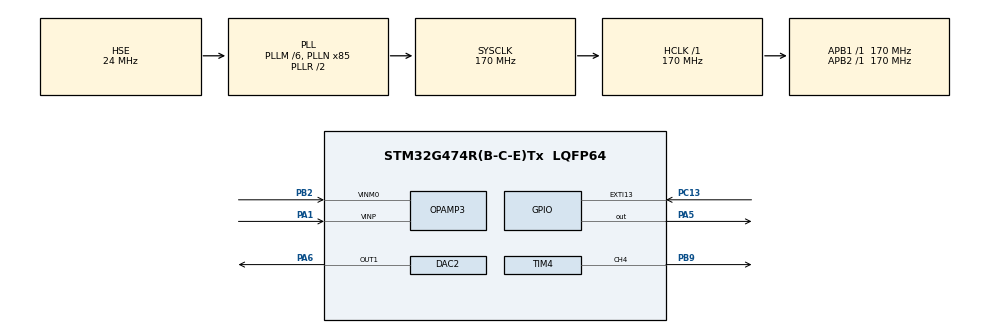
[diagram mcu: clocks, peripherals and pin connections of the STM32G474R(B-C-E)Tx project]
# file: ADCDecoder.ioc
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ADC2.AWD2HighThreshold=0xFD0
ADC2.AWD2LowThreshold=0x20
ADC2.AWDChannel-1\#ChannelRegularConversion=ADC_CHANNEL_VOPAMP3_ADC2
ADC2.Channel-1\#ChannelRegularConversion=ADC_CHANNEL_VOPAMP3_ADC2
ADC2.DMAContinuousRequests=ENABLE
ADC2.EnableAnalogWatchDog2=true
ADC2.EnableAnalogWatchDog3=false
ADC2.ExternalTrigConv=ADC_EXTERNALTRIG_T4_CC4
ADC2.GainCompensation=0
ADC2.MonitoredBy-1\#ChannelRegularConversion=ADC_ANALOGWATCHDOG_2
ADC2.NbrOfConversionFlag=1
ADC2.Offset-1\#ChannelRegularConversion=2048
ADC2.OffsetNumber-1\#ChannelRegularConversion=ADC_OFFSET_NONE
ADC2.Overrun=ADC_OVR_DATA_OVERWRITTEN
ADC2.Rank-1\#ChannelRegularConversion=1
ADC2.RegFilteringConfig-1\#ChannelRegularConversion=ADC_AWD_FILTERING_NONE
ADC2.SamplingTime-1\#ChannelRegularConversion=ADC_SAMPLETIME_2CYCLES_5
ADC2.WDG2ChannelR1=ADC_CHANNEL_VOPAMP3_ADC2
ADC2.WatchdogMode2=ADC_ANALOGWATCHDOG_SINGLE_REGINJEC
DAC2.DAC_DMADoubleDataMode-DAC_OUT1=DISABLE
DAC2.DAC_SignedFormat-DAC_OUT1=DISABLE
Dma.ADC2.1.Direction=DMA_PERIPH_TO_MEMORY
Dma.ADC2.1.EventEnable=DISABLE
Dma.ADC2.1.Instance=DMA1_Channel1
Dma.ADC2.1.MemDataAlignment=DMA_MDATAALIGN_WORD
Dma.ADC2.1.MemInc=DMA_MINC_DISABLE
Dma.ADC2.1.Mode=DMA_CIRCULAR
Dma.ADC2.1.PeriphDataAlignment=DMA_PDATAALIGN_HALFWORD
Dma.ADC2.1.PeriphInc=DMA_PINC_DISABLE
Dma.ADC2.1.Polarity=HAL_DMAMUX_REQ_GEN_RISING
Dma.ADC2.1.Priority=DMA_PRIORITY_LOW
Dma.ADC2.1.RequestNumber=1
Dma.ADC2.1.SignalID=NONE
Dma.ADC2.1.SyncEnable=DISABLE
Dma.ADC2.1.SyncPolarity=HAL_DMAMUX_SYNC_NO_EVENT
Dma.ADC2.1.SyncRequestNumber=1
Dma.ADC2.1.SyncSignalID=NONE
Dma.FMAC_READ.0.Direction=DMA_PERIPH_TO_MEMORY
Dma.FMAC_READ.0.EventEnable=DISABLE
Dma.FMAC_READ.0.Instance=DMA1_Channel3
Dma.FMAC_READ.0.MemDataAlignment=DMA_MDATAALIGN_WORD
Dma.FMAC_READ.0.MemInc=DMA_MINC_DISABLE
Dma.FMAC_READ.0.Mode=DMA_CIRCULAR
Dma.FMAC_READ.0.PeriphDataAlignment=DMA_PDATAALIGN_WORD
Dma.FMAC_READ.0.PeriphInc=DMA_PINC_DISABLE
Dma.FMAC_READ.0.Polarity=HAL_DMAMUX_REQ_GEN_RISING
Dma.FMAC_READ.0.Priority=DMA_PRIORITY_LOW
Dma.FMAC_READ.0.RequestNumber=1
Dma.FMAC_READ.0.SignalID=NONE
Dma.FMAC_READ.0.SyncEnable=DISABLE
Dma.FMAC_READ.0.SyncPolarity=HAL_DMAMUX_SYNC_NO_EVENT
Dma.FMAC_READ.0.SyncRequestNumber=1
Dma.FMAC_READ.0.SyncSignalID=NONE
Dma.MEMTOMEM.2.Direction=DMA_MEMORY_TO_MEMORY
Dma.MEMTOMEM.2.EventEnable=DISABLE
Dma.MEMTOMEM.2.Instance=DMA2_Channel2
Dma.MEMTOMEM.2.MemDataAlignment=DMA_MDATAALIGN_WORD
Dma.MEMTOMEM.2.MemInc=DMA_MINC_ENABLE
Dma.MEMTOMEM.2.Mode=DMA_NORMAL
Dma.MEMTOMEM.2.PeriphDataAlignment=DMA_PDATAALIGN_WORD
Dma.MEMTOMEM.2.PeriphInc=DMA_PINC_ENABLE
Dma.MEMTOMEM.2.Polarity=HAL_DMAMUX_REQ_GEN_RISING
Dma.MEMTOMEM.2.Priority=DMA_PRIORITY_LOW
Dma.MEMTOMEM.2.RequestNumber=1
Dma.MEMTOMEM.2.SignalID=NONE
Dma.MEMTOMEM.2.SyncEnable=DISABLE
Dma.MEMTOMEM.2.SyncPolarity=HAL_DMAMUX_SYNC_NO_EVENT
Dma.MEMTOMEM.2.SyncRequestNumber=1
Dma.MEMTOMEM.2.SyncSignalID=NONE
Dma.MEMTOMEM.3.Direction=DMA_MEMORY_TO_MEMORY
Dma.MEMTOMEM.3.EventEnable=DISABLE
Dma.MEMTOMEM.3.Instance=DMA1_Channel2
Dma.MEMTOMEM.3.MemDataAlignment=DMA_MDATAALIGN_WORD
Dma.MEMTOMEM.3.MemInc=DMA_MINC_ENABLE
Dma.MEMTOMEM.3.Mode=DMA_NORMAL
Dma.MEMTOMEM.3.PeriphDataAlignment=DMA_PDATAALIGN_WORD
Dma.MEMTOMEM.3.PeriphInc=DMA_PINC_ENABLE
Dma.MEMTOMEM.3.Polarity=HAL_DMAMUX_REQ_GEN_RISING
Dma.MEMTOMEM.3.Priority=DMA_PRIORITY_LOW
Dma.MEMTOMEM.3.RequestNumber=1
Dma.MEMTOMEM.3.SignalID=NONE
Dma.MEMTOMEM.3.SyncEnable=DISABLE
Dma.MEMTOMEM.3.SyncPolarity=HAL_DMAMUX_SYNC_NO_EVENT
Dma.MEMTOMEM.3.SyncRequestNumber=1
Dma.MEMTOMEM.3.SyncSignalID=NONE
Dma.Request0=FMAC_READ
Dma.Request1=ADC2
Dma.Request2=MEMTOMEM
Dma.Request3=MEMTOMEM
Mcu.Family=STM32G4
Mcu.Name=STM32G474R(B-C-E)Tx
Mcu.Package=LQFP64
NUCLEO-G474RE.BUTTON=1
NUCLEO-G474RE.Bsp_Common_DEMO=true
NUCLEO-G474RE.LD2=true
NUCLEO-G474RE.VCP=true
NVIC.DMA1_Channel1_IRQn=true\:0\:0\:false\:false\:true\:false\:true\:true
NVIC.DMA1_Channel2_IRQn=true\:0\:0\:false\:false\:true\:true\:true\:true
NVIC.DMA1_Channel3_IRQn=true\:0\:0\:false\:false\:true\:false\:true\:true
NVIC.DMA2_Channel2_IRQn=true\:0\:0\:false\:false\:true\:true\:true\:true
NVIC.EXTI15_10_IRQn=true\:0\:0\:false\:false\:true\:true\:true\:true
NVIC.PriorityGroup=NVIC_PRIORITYGROUP_4
NVIC.TIM1_UP_TIM16_IRQn=true\:0\:0\:false\:false\:true\:true\:true\:true
NVIC.TIM3_IRQn=true\:0\:0\:false\:false\:true\:true\:true\:true
NVIC.TIM5_IRQn=true\:0\:0\:false\:false\:true\:true\:true\:true
OPAMP3.PgaGain=OPAMP_PGA_GAIN_2_OR_MINUS_1
OPAMP3.PowerMode=OPAMP_POWERMODE_HIGHSPEED
OPAMP3.SelfCalibration=Enable
OPAMP3.UserTrimming=OPAMP_TRIMMING_USER
PA1.Mode=PGA Internally connected_IO0_IO1_BIAS
PA1.Signal=OPAMP3_VINP
PA13.GPIO_Label=T_SWDIO
PA13.Signal=SYS_JTMS-SWDIO
PA14.GPIO_Label=T_SWCLK
PA14.Signal=SYS_JTCK-SWCLK
PA2.Signal=LPUART1_TX
PA3.Signal=LPUART1_RX
PA5.Signal=GPIO_Output
PA6.Signal=COMP_DAC21_group
PB2.Mode=PGA Internally connected_IO0_IO1_BIAS
PB2.Signal=OPAMP3_VINM0
PB3.GPIO_Label=T_SWO
PB3.Signal=SYS_JTDO-SWO
PB9.Signal=S_TIM4_CH4
PC13.Signal=GPXTI13
PC14-OSC32_IN.GPIO_Label=RCC_OSC32_IN
PC14-OSC32_IN.Signal=RCC_OSC32_IN
PC15-OSC32_OUT.GPIO_Label=RCC_OSC32_OUT
PC15-OSC32_OUT.Signal=RCC_OSC32_OUT
PF0-OSC_IN.GPIO_Label=RCC_OSC_IN
PF0-OSC_IN.Mode=HSE-External-Oscillator
PF0-OSC_IN.Signal=RCC_OSC_IN
PF1-OSC_OUT.GPIO_Label=RCC_OSC_OUT
PF1-OSC_OUT.Mode=HSE-External-Oscillator
PF1-OSC_OUT.Signal=RCC_OSC_OUT
ProjectManager.HeapSize=0x200
ProjectManager.StackSize=0x400
ProjectManager.TargetToolchain=STM32CubeIDE
RCC.ADC12Freq_Value=170000000
RCC.ADC345Freq_Value=170000000
RCC.AHBFreq_Value=170000000
RCC.APB1Freq_Value=170000000
RCC.APB1TimFreq_Value=170000000
RCC.APB2Freq_Value=170000000
RCC.APB2TimFreq_Value=170000000
RCC.CK48CLockSelection=RCC_USBCLKSOURCE_HSI48
RCC.CortexFreq_Value=170000000
RCC.EXTERNAL_CLOCK_VALUE=12288000
RCC.HCLKFreq_Value=170000000
RCC.HSE_VALUE=24000000
RCC.HSI48_VALUE=48000000
RCC.HSI_VALUE=16000000
RCC.LSE_VALUE=32768
RCC.PLLM=RCC_PLLM_DIV6
RCC.PLLN=85
RCC.PLLSourceVirtual=RCC_PLLSOURCE_HSE
RCC.RTCClockSelection=RCC_RTCCLKSOURCE_LSE
RCC.SYSCLKFreq_VALUE=170000000
RCC.SYSCLKSource=RCC_SYSCLKSOURCE_PLLCLK
RCC.USBFreq_Value=48000000
RCC.VCOOutputFreq_Value=340000000
RNG.ClockErrorDetection=RNG_CED_DISABLE
SH.COMP_DAC21_group.0=DAC2_OUT1,DAC_OUT1
SH.S_TIM4_CH4.0=TIM4_CH4,PWM Generation4 CH4
TIM1.PeriodNoDither=49
TIM1.Prescaler=16
TIM2.Prescaler=16
TIM3.TIM3_ETR_REMAP-ClockSourceETR_Mode2_Remap_TIM3=TIM_TIM3_ETR_ADC2_AWD2
TIM3.TIM_MasterOutputTrigger=TIM_TRGO_RESET
TIM4.Channel-PWM\ Generation4\ CH4=TIM_CHANNEL_4
TIM4.PeriodNoDither=424
TIM4.Prescaler=0
TIM4.PulseNoDither_4=212
TIM5.AutoReloadPreload=TIM_AUTORELOAD_PRELOAD_DISABLE
TIM5.PeriodNoDither=999999
TIM5.Prescaler=169
VP_ADC2_OPAMP_INTERNAL3.Mode=IN-OPAMP3
VP_FMAC_VS_FMAC.Mode=FMAC_Activate
VP_NUCLEO-G474RE_VS_BSP_COMMON.Mode=COMMON
VP_RNG_VS_RNG.Mode=RNG_Activate
VP_SYS_VS_DBSignals.Mode=DisableDeadBatterySignals
VP_TIM1_VS_ClockSourceINT.Mode=Internal
VP_TIM2_VS_ClockSourceINT.Mode=Internal
VP_TIM3_VS_NoETR.Mode=ClockSourceETR_Mode2_Remap_TIM3
VP_TIM4_VS_ClockSourceINT.Mode=Internal
VP_TIM5_VS_ClockSourceINT.Mode=Internal
board=NUCLEO-G474RE

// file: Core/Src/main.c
/* USER CODE BEGIN Header */
/**
  ******************************************************************************
  * @file           : main.c
  * @brief          : Main program body
  ******************************************************************************
  * @attention
  *
  * Copyright (c) 2024 STMicroelectronics.
  * All rights reserved.
  *
  * This software is licensed under terms that can be found in the LICENSE file
  * in the root directory of this software component.
  * If no LICENSE file comes with this software, it is provided AS-IS.
  *
  ******************************************************************************
  */
/* USER CODE END Header */
#include "main.h"
#include "adc.h"
#include "dac.h"
#include "dma.h"
#include "fmac.h"
#include "opamp.h"
#include "rng.h"
#include "tim.h"
#include "gpio.h"

COM_InitTypeDef BspCOMInit;
__IO uint32_t BspButtonState = BUTTON_RELEASED;

void SystemClock_Config(void);

/* USER CODE BEGIN 0 */
extern void main_cpp_begin(void);
/* USER CODE END 0 */

int main(void)
{

  /* MCU Configuration--------------------------------------------------------*/

  /* Reset of all peripherals, Initializes the Flash interface and the Systick. */
  HAL_Init();

  /* Configure the system clock */
  SystemClock_Config();

  /* Initialize all configured peripherals */
  MX_GPIO_Init();
  MX_DMA_Init();
  MX_FMAC_Init();
  MX_ADC2_Init();
  MX_TIM4_Init();
  MX_DAC2_Init();
  MX_OPAMP3_Init();
  MX_TIM2_Init();
  MX_TIM3_Init();
  MX_TIM5_Init();
  MX_TIM1_Init();
  MX_RNG_Init();

  /* Initialize led */
  BSP_LED_Init(LED_GREEN);

  /* Initialize USER push-button, will be used to trigger an interrupt each time it's pressed.*/
  BSP_PB_Init(BUTTON_USER, BUTTON_MODE_EXTI);

  /* Initialize COM1 port (115200, 8 bits (7-bit data + 1 stop bit), no parity */
  BspCOMInit.BaudRate   = 115200;
  BspCOMInit.WordLength = COM_WORDLENGTH_8B;
  BspCOMInit.StopBits   = COM_STOPBITS_1;
  BspCOMInit.Parity     = COM_PARITY_NONE;
  BspCOMInit.HwFlowCtl  = COM_HWCONTROL_NONE;
  if (BSP_COM_Init(COM1, &BspCOMInit) != BSP_ERROR_NONE)
  {
    Error_Handler();
  }

  /* USER CODE BEGIN BSP */

  /* -- Sample board code to send message over COM1 port ---- */
  printf("Welcome to STM32 world !\n\r");

  /* -- Sample board code to switch on led ---- */
  BSP_LED_On(LED_GREEN);

  /* USER CODE END BSP */

  /* Infinite loop */
  /* USER CODE BEGIN WHILE */

  SCB->SHCSR |= SCB_SHCSR_BUSFAULTENA_Msk | SCB_SHCSR_MEMFAULTENA_Msk | SCB_SHCSR_USGFAULTENA_Msk;

  main_cpp_begin();
  return 0;

  while (1)
  {

    /* -- Sample board code for User push-button in interrupt mode ---- */
    if (BspButtonState == BUTTON_PRESSED)
    {
      /* Update button state */
      BspButtonState = BUTTON_RELEASED;
      /* -- Sample board code to toggle led ---- */
      BSP_LED_Toggle(LED_GREEN);

      /* ..... Perform your action ..... */
    }
    /* USER CODE END WHILE */

  }
}

void SystemClock_Config(void)
{
  RCC_OscInitTypeDef RCC_OscInitStruct = {0};
  RCC_ClkInitTypeDef RCC_ClkInitStruct = {0};

  /** Configure the main internal regulator output voltage
  */
  HAL_PWREx_ControlVoltageScaling(PWR_REGULATOR_VOLTAGE_SCALE1_BOOST);

  /** Initializes the RCC Oscillators according to the specified parameters
  * in the RCC_OscInitTypeDef structure.
  */
  RCC_OscInitStruct.OscillatorType = RCC_OSCILLATORTYPE_HSI48|RCC_OSCILLATORTYPE_HSE;
  RCC_OscInitStruct.HSEState = RCC_HSE_ON;
  RCC_OscInitStruct.HSI48State = RCC_HSI48_ON;
  RCC_OscInitStruct.PLL.PLLState = RCC_PLL_ON;
  RCC_OscInitStruct.PLL.PLLSource = RCC_PLLSOURCE_HSE;
  RCC_OscInitStruct.PLL.PLLM = RCC_PLLM_DIV6;
  RCC_OscInitStruct.PLL.PLLN = 85;
  RCC_OscInitStruct.PLL.PLLP = RCC_PLLP_DIV2;
  RCC_OscInitStruct.PLL.PLLQ = RCC_PLLQ_DIV2;
  RCC_OscInitStruct.PLL.PLLR = RCC_PLLR_DIV2;
  if (HAL_RCC_OscConfig(&RCC_OscInitStruct) != HAL_OK)
  {
    Error_Handler();
  }

  /** Initializes the CPU, AHB and APB buses clocks
  */
  RCC_ClkInitStruct.ClockType = RCC_CLOCKTYPE_HCLK|RCC_CLOCKTYPE_SYSCLK
                              |RCC_CLOCKTYPE_PCLK1|RCC_CLOCKTYPE_PCLK2;
  RCC_ClkInitStruct.SYSCLKSource = RCC_SYSCLKSOURCE_PLLCLK;
  RCC_ClkInitStruct.AHBCLKDivider = RCC_SYSCLK_DIV1;
  RCC_ClkInitStruct.APB1CLKDivider = RCC_HCLK_DIV1;
  RCC_ClkInitStruct.APB2CLKDivider = RCC_HCLK_DIV1;

  if (HAL_RCC_ClockConfig(&RCC_ClkInitStruct, FLASH_LATENCY_4) != HAL_OK)
  {
    Error_Handler();
  }
}

/**
  * @brief BSP Push Button callback
  * @param Button Specifies the pressed button
  * @retval None
  */
void BSP_PB_Callback(Button_TypeDef Button)
{
  if (Button == BUTTON_USER)
  {
    BspButtonState = BUTTON_PRESSED;
  }
}

void Error_Handler(void)
{
  __disable_irq();
  while (1)
  {
  }
}
